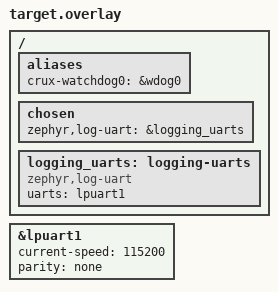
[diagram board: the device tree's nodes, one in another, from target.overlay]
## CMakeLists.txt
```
# SPDX-License-Identifier: Apache-2.0
# RT1060-EVKB bench image of the integrated management composition (HTTPS web, the command line over SSH and
# SFTP), on the Wolf profile: docs/rt1060-management-image-feasibility.md. Row C1 promoted the compile vehicle of
# stage 0 to a bench composition with a declaration (bench_declaration.json) and guards at three levels
# (bench_guard.cmake, src/bench_guard.h, Kconfig.bench). The directory keeps its name because the evidence of
# stage 0 names it. IT REFUSES TO START: CRUX_BENCH_RUN_REFUSED below is the switch, and nothing here is approved
# to run on a board. Its test certificate is not used (the certificate is generated), its SSH host key is held in
# test form (D5), and its first account comes from a password file outside the repository (D3, row C4).
# It needs the crux-secure-management west group, and a ZEPHYR_BASE with the TLS socket patch
# (scripts/prepare-wolf-tls-zephyr.sh), which the guard checks. It reuses the source lists of
# tests/native/management_composition, which refuses a board on purpose, so those lists are repeated in
# management_target.cmake and are checked there.
cmake_minimum_required(VERSION 3.20.0)
get_filename_component(CRUX_ROOT "${CMAKE_CURRENT_LIST_DIR}/../../.." ABSOLUTE)
set(composition_dir "${CRUX_ROOT}/tests/native/management_composition")
set(services_dir "${CRUX_ROOT}/tests/native/management_services")
set(EXTRA_CONF_FILE
    "${CRUX_ROOT}/tests/native/tls_offload_probe/wolf.conf"
    "${composition_dir}/profile-psa.conf"
    "${CRUX_ROOT}/components/ssh/ports/zephyr/wolf-ssh.conf"
    "${CMAKE_CURRENT_LIST_DIR}/target.conf")
set(DTC_OVERLAY_FILE
    "${CRUX_ROOT}/samples/controller/zephyr/m3-network.overlay"
    "${CMAKE_CURRENT_LIST_DIR}/target.overlay"
    "${CMAKE_CURRENT_LIST_DIR}/ram_disk.overlay")
list(APPEND ZEPHYR_EXTRA_MODULES "${CRUX_ROOT}")
find_package(Zephyr REQUIRED HINTS $ENV{ZEPHYR_BASE})
# The declaration, which no native image sets. bench_guard.cmake refuses a build without it.
set(CRUX_MANAGEMENT_BENCH_IMAGE ON)
# The refusal in main(). Removing it is a reviewed change after the approval of the board stage.
set(CRUX_BENCH_RUN_REFUSED ON)
project(crux_management_rt1060_compile LANGUAGES C)
include("${CMAKE_CURRENT_LIST_DIR}/management_target.cmake")
crux_management_target_compose()
include(${CRUX_ROOT}/cmake/CruxWebAssets.cmake)
include(${CRUX_ROOT}/cmake/CruxWebRoutes.cmake)
set(route_sources ${CRUX_WEB_SESSION_ROUTES} ${CRUX_WEB_MANAGEMENT_ROUTES}
    ${CRUX_WEB_MANAGEMENT_NETWORK_ROUTES})
target_sources(app PRIVATE src/main.c src/ssh_target.c src/bench_first_account.c ${route_sources})
# The file medium of row C3: the decision and its Zephyr glue, the only sources that mount it or format a RAM disk.
target_sources(app PRIVATE src/bench_medium.c src/bench_medium_fs.c)
if(CRUX_BENCH_RUN_REFUSED)
    target_compile_definitions(app PRIVATE CRUX_BENCH_RUN_REFUSED=1)
else()
    target_compile_definitions(app PRIVATE CRUX_BENCH_RUN_REFUSED=0)
endif()
target_include_directories(app PRIVATE src)
# Row C2: the UART report of stack watermarks, heap and the certificate fingerprint. report/ holds the parts that
# need no bench symbol (and that the host test and tests/native/bench_report build), src/bench_report.c the glue.
target_sources(app PRIVATE src/bench_report.c report/bench_report_core.c report/bench_report_format.c
    report/bench_report_policy.c)
target_include_directories(app PRIVATE report)
crux_web_assets(app FOLDER ${services_dir}/site STYLE strict)
crux_web_routes(app SOURCES ${route_sources} ZEPHYR_RESOURCES REVIEWED ${services_dir}/reviewed-routes.txt)
# Row C4 (D3): the first account's step, and its password file, which is checked here and whose bytes are embedded
# (bench_first_account.cmake). A missing, empty or short file stops the configuration.
include("${CMAKE_CURRENT_LIST_DIR}/bench_first_account.cmake")
target_sources(app PRIVATE first_account/bench_first_account_provision.c)
target_include_directories(app PRIVATE first_account)
crux_bench_first_account_prepare()
crux_bench_manifest()
# Row C9 (D11): wolfCrypt is built without RSA (CONFIG_WOLFSSL_RSA=n in target.conf, refused on at every guard level),
# and the linked image is checked for RSA code too: a module update or another definition that brings it back with the
# setting off fails the build here. It runs after the final link, and a missing image or nm is a failure, never a pass.
# zephyr_final is Zephyr's name for the final link. ZEPHYR_FINAL_EXECUTABLE is set inside Zephyr's own directory scope and
# is not visible here, so the name is written out: a rename stops the configuration at add_dependencies.
crux_bench_find_python(crux_bench_rsa_python)
add_custom_target(bench_rsa_symbols ALL
    COMMAND "${crux_bench_rsa_python}" "${CMAKE_CURRENT_LIST_DIR}/check_bench_rsa_symbols.py" --nm "${CMAKE_NM}"
            "$<TARGET_FILE:zephyr_final>"
    COMMENT "Checking the linked bench image for RSA code (D11, row C9)"
    VERBATIM)
add_dependencies(bench_rsa_symbols zephyr_final)
```

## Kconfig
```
# SPDX-License-Identifier: Apache-2.0
# The bench symbols of the RT1060-EVKB bench image. Only this application has them: any other build that
# assigns one is refused by Kconfig as an undefined symbol.
mainmenu "RT1060-EVKB bench image of the integrated management composition"

rsource "Kconfig.bench"
source "Kconfig.zephyr"
```

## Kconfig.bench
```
# SPDX-License-Identifier: Apache-2.0
# The configuration level of the bench guards (docs/rt1060-management-image-feasibility.md). A test form cannot
# take effect unless the declaration holds, and the declaration holds only on this board with the TRNG and no
# test entropy. Zephyr reports an assignment that Kconfig drops, because a dependency is not met, as a WARNING
# and goes on (the finding of docs/ssh-integrated-image.md). The CMake level turns it into a refusal: it
# requires CONFIG_CRUX_MANAGEMENT_BENCH_IMAGE and every selected form to be set.

config CRUX_MANAGEMENT_BENCH_IMAGE
	bool "Declared RT1060-EVKB rev B bench image of the integrated management composition"
	depends on BOARD_MIMXRT1060_EVK_MIMXRT1062_QSPI && BOARD_REVISION = "B"
	depends on ENTROPY_MCUX_TRNG && !TEST_RANDOM_GENERATOR && !FAKE_ENTROPY_NATIVE_SIM
	depends on !NET_DHCPV4 && !NET_IPV6
	depends on !WOLFSSL_RSA
	depends on !WOLFSSL_HAS_SETTINGS_FILE
	depends on NET_TCP_ISN_RFC6528
	help
	  The declaration that allows the test forms below, for this board and this bench only. It is the
	  Kconfig level of three: the CMake level is bench_guard.cmake and the C level is src/bench_guard.h.
	  It needs the TRNG driver and no test entropy, and no DHCP and no IPv6, because the listeners
	  answer on the one bench address (D10). It needs wolfCrypt built without RSA (D11, row C9): the declared
	  profile uses none, and a wolfSSL settings file would hide whether RSA is built. It needs the RFC 6528 initial
	  sequence number (D-c, row C11), which the build-local Zephyr copy's second patch makes fail closed: without it
	  Zephyr takes the number from sys_rand32_get() and the patch protects nothing.

if CRUX_MANAGEMENT_BENCH_IMAGE

# A test form is a way of doing something that is acceptable on a bench and is not acceptable as a
# product. Each one depends on the declaration. A symbol added here must start with CRUX_BENCH_, so that
# check_bench_guard.py finds it, and must be listed in bench_declaration.json.

config CRUX_BENCH_TEST_HOST_KEY
	bool "SSH host key in test form: a static buffer, never wiped (D5)"
	help
	  The credential store generates the key from the TRNG and the provider borrows it from a static
	  buffer for the life of the image. No product rule exists for holding and wiping a host key.

config CRUX_BENCH_NO_TIME_SOURCE
	bool "No time source: times are relative to boot (D7)"
	depends on !RTC
	help
	  Zephyr's realtime clock, which nothing sets. Certificates and events carry boot-relative times.

config CRUX_BENCH_FILE_RAM_DISK
	bool "RAM disk as the file backend (D2)"
	depends on DISK_DRIVER_RAM && !DISK_DRIVER_SDMMC
	help
	  The file service, the credential store and the events' files live on a RAM disk in SDRAM. Nothing
	  persists across a reset, and no card is touched: the SD card driver is not in the image. The
	  composition formats the RAM disk when it mounts blank, and never formats anything else
	  (src/bench_medium.c).

config CRUX_BENCH_FILE_MICROSD
	bool "microSD card as the file backend (D2). Reserved for a later run: not selected in this image"
	depends on DISK_DRIVER_SDMMC && !DISK_DRIVER_RAM
	help
	  The existing microSD provider. A later run selects it by changing the state of this form in
	  bench_declaration.json to selected, with the owner's approval of a card run and the M4 microSD
	  tools. Even then a mount that fails is reported and the card is never formatted by this image.

config CRUX_BENCH_FIRST_ACCOUNT_FILE
	bool "First account from a password in a file outside the repository (D3)"
	help
	  The password is read at configuration from the file that CRUX_BENCH_PASSWORD_FILE names, which must be private,
	  outside every git work tree and at least 16 characters, and is embedded in this image as plaintext in read-only
	  data, because Access takes a plaintext password and derives its own record. The build records the file's
	  SHA-256 in the manifest and never the password. A product creates its first account in a serial setup step.

endif # CRUX_MANAGEMENT_BENCH_IMAGE
```

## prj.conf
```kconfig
# The settings are in target.conf, which CMakeLists.txt merges last, after the Wolf profile files.
```

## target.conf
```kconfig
# RT1060-EVKB rev B bench image. Every size here is a first, unmeasured choice: the report says which.
# The bench declaration at the Kconfig level, and the test forms that it allows (Kconfig.bench). The reserved
# form CRUX_BENCH_FILE_MICROSD (a later run) stays unset until its row implements it: bench_guard.cmake refuses it
# before that.
CONFIG_CRUX_MANAGEMENT_BENCH_IMAGE=y
CONFIG_CRUX_BENCH_TEST_HOST_KEY=y
CONFIG_CRUX_BENCH_NO_TIME_SOURCE=y
# D2, row C3: the file backend is a RAM disk. See "The file backend" below.
CONFIG_CRUX_BENCH_FILE_RAM_DISK=y
# D3, row C4: the first account from a password file outside the repository (bench_first_account.cmake).
CONFIG_CRUX_BENCH_FIRST_ACCOUNT_FILE=y

# D11, row C9: wolfCrypt without RSA. The declared profile (TLS 1.3 with P-256, SSH with Ed25519 and
# ecdsa-sha2-nistp256, ECDSA and Ed25519 stored keys) uses none. The module's option defaults to y, and n defines
# NO_RSA, which drops wolfCrypt's RSA, the single-precision RSA math and wolfPSA's RSA together. Every guard level
# refuses it being on, and check_bench_rsa_symbols.py checks the linked image (docs/rt1060-bench-trim-rsa.md).
CONFIG_WOLFSSL_RSA=n

# D10: both listeners answer on the bench address only, which is the address of main.c and the declaration.
CONFIG_CRUX_WEB_BIND_ADDRESS="192.168.77.2"
CONFIG_CRUX_SSH_BIND_ADDRESS="192.168.77.2"
CONFIG_STD_C17=y
CONFIG_CRUX_PILOT_MODULE=y
CONFIG_MAIN_STACK_SIZE=16384
CONFIG_INIT_STACKS=y
CONFIG_THREAD_STACK_INFO=y
CONFIG_THREAD_NAME=y
CONFIG_THREAD_MONITOR=y
CONFIG_SHELL=n

# Crux Logging, which the security events write to: the deferred UART backend on LPUART1, as
# tests/logging_consumer configures it for this board. printk goes through it, so there is one writer.
CONFIG_PRINTK=y
CONFIG_CRUX_LOGGING=y
CONFIG_SERIAL=y
CONFIG_LOG=y
CONFIG_LOG_MODE_DEFERRED=y
CONFIG_LOG_MODE_OVERFLOW=n
CONFIG_LOG_BLOCK_IN_THREAD=n
CONFIG_LOG_PROCESS_THREAD=y
CONFIG_LOG_PROCESS_THREAD_STACK_SIZE=2048
CONFIG_LOG_PROCESS_THREAD_CUSTOM_PRIORITY=y
CONFIG_LOG_PROCESS_THREAD_PRIORITY=14
CONFIG_LOG_BUFFER_SIZE=4096
CONFIG_LOG_MAX_LEVEL=4
CONFIG_LOG_DEFAULT_LEVEL=0
CONFIG_LOG_RUNTIME_FILTERING=n
CONFIG_LOG_BACKEND_UART=y
CONFIG_LOG_BACKEND_UART_ASYNC=n
CONFIG_LOG_BACKEND_SHOW_LEVEL=y
CONFIG_UART_CONSOLE=y
CONFIG_LOG_PRINTK=y
CONFIG_STDOUT_CONSOLE=n
CONFIG_CONSOLE_HANDLER=n
CONFIG_CONSOLE_SUBSYS=n
CONFIG_EARLY_CONSOLE=n
CONFIG_BOOT_BANNER=n

# Ethernet and the TLS socket layer, as the M5 image and tests/zephyr/web_compile have them.
CONFIG_NETWORKING=y
CONFIG_NET_L2_ETHERNET=y
CONFIG_NET_IPV4=y
CONFIG_NET_IPV6=n
CONFIG_NET_TCP=y
# D-c, row C11: the TCP initial sequence number is the keyed one (RFC 6528, Zephyr's default), which the second patch
# of the build-local Zephyr copy makes fail closed. The three bench guards require it.
CONFIG_NET_TCP_ISN_RFC6528=y
CONFIG_NET_UDP=y
CONFIG_NET_SOCKETS=y
CONFIG_NET_DHCPV4=n
CONFIG_NET_CONFIG_SETTINGS=n
CONFIG_NET_BUF_POOL_USAGE=y
CONFIG_NET_MAX_CONTEXTS=32
CONFIG_NET_MAX_CONN=32
CONFIG_PHY_MONITOR_PERIOD=500
CONFIG_NET_SOCKETS_SOCKOPT_TLS=y
CONFIG_TLS_CREDENTIALS=y
CONFIG_TLS_MAX_CREDENTIALS_NUMBER=4
CONFIG_NET_SOCKETS_TLS_MAX_CONTEXTS=6
CONFIG_ZVFS_OPEN_MAX=48
CONFIG_ZVFS_POLL_MAX=24
CONFIG_ZVFS_EVENTFD=y
CONFIG_POSIX_API=y
CONFIG_POSIX_TIMERS=y
CONFIG_POSIX_THREADS=y
CONFIG_GPIO=y

# Entropy: the i.MX RT TRNG through its driver. No test generator, no fake entropy.
CONFIG_ENTROPY_GENERATOR=y
CONFIG_HWINFO=y

# The Wolf profile's arena: TLS and SSH allocate from one C library arena, in SDRAM on this board. 1 MiB since row C6:
# the paper peak of the declared sessions is 347,104 B (bench_declaration.json, heap) and stays under half of it.
CONFIG_COMMON_LIBC_MALLOC_ARENA_SIZE=1048576
CONFIG_SYS_HEAP_RUNTIME_STATS=y

# Web adapter, HTTPS only.
CONFIG_CRUX_WEB=y
# The HTTP server thread runs each TLS handshake inside accept. The static estimate of one handshake path is 4,272 B
# against the default of 4,096 B, so the owner asked for 8,192 B from the start (2026-11-08). Row C2 prints its stack
# watermark on the UART, and check_bench_uart.py fails a run that leaves under 25 percent of it (2,048 B) unused:
# the next size is 16,384 B, taken only if a board run says so. The bench declaration pins no size.
CONFIG_HTTP_SERVER_STACK_SIZE=8192

# SSH, CLI and SFTP, with the provider sizes at their defaults.
CONFIG_CRUX_SSH=y
CONFIG_CRUX_SSH_CLI=y
CONFIG_CRUX_SSH_SFTP=y
CONFIG_CRUX_SSH_PORT=22
CONFIG_CRUX_SSH_MAX_CONNECTIONS=4

# Crux capabilities the composition links.
# No CONFIG_RTC: with it the wolfSSL Zephyr port looks up a devicetree label `rtc`, which this board does not
# have (its RTC is the snvs_rtc and counter_rtc nodes, behind the `rtc` alias), and wc_port.c does not compile.
# The wall clock is then Zephyr's realtime clock, which no source sets (D7): see the report.
CONFIG_CRUX_TIME=y
CONFIG_CRUX_THREAD=y
CONFIG_CRUX_THREAD_STACK_BYTES=8192
CONFIG_CRUX_SYNC=y
CONFIG_CRUX_SYNC_MUTEX_COUNT=16
CONFIG_CRUX_NETIF=y
CONFIG_CRUX_SYSTEM=y
CONFIG_WATCHDOG=y
CONFIG_REBOOT=y

# The file backend (D2, row C3): the File service on FatFs over a RAM disk of 512 KiB in SDRAM, with no card driver in
# the image. Nothing persists across a reset: accounts, keys, the certificate and the events are lost. The disk is
# the node of ram_disk.overlay, and src/bench_medium.c formats it when it mounts blank, and never formats a card.
# CRUX_BENCH_FILE_MICROSD, the microSD provider with CRUX_FILE_FATFS_RT1060, the SD card driver and the USDHC host
# are for a later run and are refused here until the declaration says so.
CONFIG_FILE_SYSTEM=y
CONFIG_FILE_SYSTEM_MKFS=y
CONFIG_FAT_FILESYSTEM_ELM=y
CONFIG_FS_FATFS_LFN=y
CONFIG_FS_FATFS_LFN_MODE_STACK=y
CONFIG_FS_FATFS_MAX_LFN=127
CONFIG_FS_FATFS_MOUNT_MKFS=n
CONFIG_FS_FATFS_REENTRANT=y
CONFIG_FS_FATFS_NUM_FILES=6
CONFIG_DISK_DRIVERS=y
CONFIG_DISK_DRIVER_RAM=y
CONFIG_CRUX_FILE_FATFS_RT1060_RAM_DISK=y
# Zephyr turns the SD card driver and the USDHC host on by default when the board's devicetree has the card's node
# (it has), so this image turns them off. The first configure of this image showed it: the RAM disk form dropped to n
# and the CMake guard refused. With them off the image has no card driver, and no card to mount or format.
CONFIG_DISK_DRIVER_SDMMC=n
CONFIG_IMX_USDHC=n

# Row C2: what the UART report reads. TCP segments per interface tell it that a client is talking, and the SSH
# provider names its threads and keeps the figure of each worker that ended. The stack settings it also needs
# (THREAD_MONITOR, THREAD_STACK_INFO, THREAD_NAME, INIT_STACKS) and SYS_HEAP_RUNTIME_STATS are set above.
CONFIG_NET_STATISTICS=y
CONFIG_NET_STATISTICS_PER_INTERFACE=y
CONFIG_NET_STATISTICS_TCP=y
CONFIG_CRUX_SSH_STACK_REPORT=y

# Row C6: the network buffers, the TCP windows and the arena, for HTTPS, SSH and SFTP at the session sizes of D9. Every
# number is a paper rule that docs/rt1060-bench-network-buffers.md derives, and nothing is measured on a board:
# bench_guard.cmake refuses a pool under its need, a window that is not the declared one and an arena under its need
# (bench_declaration.json, network_buffers and heap), and the report's BENCH-POOL and BENCH-NET lines are what a board
# run reads to confirm or change them.
# Data buffers stay at Zephyr's 128 B. A full Ethernet frame is 12 of them, and the counts are sized in frames.
CONFIG_NET_BUF_DATA_SIZE=128
# The window is 4 segments of 1,460 B, set both ways. Left at 0, Zephyr takes a third of the pool for it, which at
# these pools is 32 KiB and 5 times the 6 frames of the driver's receive ring.
CONFIG_NET_TCP_MAX_RECV_WINDOW_SIZE=5840
CONFIG_NET_TCP_MAX_SEND_WINDOW_SIZE=5840
# 11 connections (7 slots and the web listener's backlog of 4) each holding a window of 512 B segments unread, and the
# driver's ring, with 25 percent: 915 buffers needed. Transmit: 7 queued windows and 7 senders' segments (12 buffers and
# a header buffer each): 517.
CONFIG_NET_BUF_RX_COUNT=1024
CONFIG_NET_BUF_TX_COUNT=768
CONFIG_NET_PKT_RX_COUNT=192
CONFIG_NET_PKT_TX_COUNT=32
# The driver's own default, and the session sizes (D9) and the web backlog, written down because the rule reads them.
CONFIG_ETH_NXP_ENET_RX_BUFFERS=6
CONFIG_HTTP_SERVER_MAX_CLIENTS=3
CONFIG_CRUX_WEB_BACKLOG=4
CONFIG_CRUX_SSH_WINDOW_BYTES=16384
# The pools' high-water marks, for the BENCH-POOL lines of the report. Packets are slabs, which keep no mark by default.
CONFIG_MEM_SLAB_TRACE_MAX_UTILIZATION=y
```

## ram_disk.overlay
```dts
/* SPDX-License-Identifier: Apache-2.0 */
/* The RAM disk of the RT1060-EVKB bench image (row C3, decision D2): the file backend of the first board run.
 * 524,288 B (512 KiB) in the SDRAM, which holds all RAM of this image. It is the .bss of the RAM disk driver, so it is
 * zero at every boot and nothing survives a reset. The size and its reasoning are in
 * docs/rt1060-management-image-feasibility.md; tests/native/management_rt1060_ram_disk formats exactly this node on
 * native_sim and fills it with the largest content the image's File service allows. The node is applied with
 * every build of this directory and costs nothing unless CONFIG_DISK_DRIVER_RAM is on, which the CMake guard
 * ties to the declared RAM disk form. */
/ {
    bench_ram_disk: ramdisk0 {
        compatible = "zephyr,ram-disk";
        disk-name = "RAM";
        sector-size = <512>;
        sector-count = <1024>;
    };
};
```

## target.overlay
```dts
/* SPDX-License-Identifier: Apache-2.0 */
/* The watchdog that Crux System looks up, as tests/system_consumer does for this board. */
/ { aliases { crux-watchdog0 = &wdog0; }; };

/* Crux Logging on LPUART1, the board's debug UART, as tests/logging_consumer does for this board. */
/ {
    chosen { zephyr,log-uart = &logging_uarts; };
    logging_uarts: logging-uarts {
        compatible = "zephyr,log-uart";
        uarts = <&lpuart1>;
    };
};
&lpuart1 { status = "okay"; current-speed = <115200>; parity = "none"; };
```

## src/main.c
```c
/*
 * RT1060-EVKB bench image of the integrated management composition (HTTPS web, the command line
 * over SSH and SFTP), under the bench declaration of bench_declaration.json. The test forms in it
 * (the SSH host key as a static buffer, no time source) are accepted only under that declaration.
 * The static address is the M5 image's, and the listeners answer on it only. See
 * docs/rt1060-management-image-feasibility.md.
 *
 * THIS IMAGE REFUSES TO START. Rows C2 to C9 are not done, the first account (D3) has no
 * implementation, the file backend is still the microSD provider, and the board stage has no
 * approval. Nothing here is a statement that the image may run on a board.
 */
#include "bench_first_account.h"
#include "bench_guard.h"
#include "bench_report.h"
#include "crux_native_management.h"
#include "crux_native_management_services.h"
#include "entropy_boot.h"
#include "ssh_target.h"

#include <errno.h>
#include <zephyr/kernel.h>
#include <zephyr/net/net_if.h>
#include <zephyr/sys/printk.h>

#ifndef CRUX_BENCH_RUN_REFUSED
#error "CMake sets CRUX_BENCH_RUN_REFUSED: 1 while the image refuses to start"
#endif

/* The bench address and netmask of the declaration, set before any listener starts, as
 * tests/networking_physical/main.c does for the M5 image. */
static bool static_address_up(void)
{
    struct net_if *iface = net_if_get_default();
    struct net_in_addr address, mask;

    if (iface == NULL || net_addr_pton(NET_AF_INET, CRUX_BENCH_ADDRESS, &address) != 0 ||
        net_addr_pton(NET_AF_INET, CRUX_BENCH_NETMASK, &mask) != 0 ||
        net_if_ipv4_addr_add(iface, &address, NET_ADDR_MANUAL, 0) == NULL ||
        !net_if_ipv4_set_netmask_by_addr(iface, &address, &mask)) {
        return false;
    }
    int status = net_if_up(iface);
    return status == 0 || status == -EALREADY;
}

/* D10 at run time: the interface has the bench address and no other IPv4 address, so that a
 * listener cannot answer on one that the declaration does not name. */
static bool only_bench_address(void)
{
    struct net_if *iface = net_if_get_default();
    struct net_in_addr address;
    struct net_if_ipv4 *ipv4;
    size_t used = 0;

    if (iface == NULL || net_addr_pton(NET_AF_INET, CRUX_BENCH_ADDRESS, &address) != 0 ||
        net_if_config_ipv4_get(iface, &ipv4) != 0 || ipv4 == NULL) {
        return false;
    }
    for (size_t i = 0; i < NET_IF_MAX_IPV4_ADDR; i++) {
        if (!ipv4->unicast[i].ipv4.is_used) {
            continue;
        }
        used++;
        if (!net_ipv4_addr_cmp(&ipv4->unicast[i].ipv4.address.in_addr, &address)) {
            return false;
        }
    }
    return used == 1u;
}

/* The refusal: the image is bootable, because a QSPI image needs its boot header, and it stops
 * here. The volatile read keeps all of the composition linked, so that the sizes in the report stay
 * those of the composition. The switch is CRUX_BENCH_RUN_REFUSED in ../CMakeLists.txt, and removing
 * it is a reviewed change that follows the approval of the board stage. */
static volatile const bool run_refused = CRUX_BENCH_RUN_REFUSED;

static void banner(void)
{
    printk("BENCH image=%s declaration=CRUX_MANAGEMENT_BENCH_IMAGE board=%s address=%s/%d\n",
           CRUX_BENCH_IMAGE_ID, CONFIG_BOARD_TARGET, CRUX_BENCH_ADDRESS, CRUX_BENCH_PREFIX_LENGTH);
    printk("BENCH test forms: host_key=%d no_time_source=%d ram_disk=%d first_account_file=%d\n",
           IS_ENABLED(CONFIG_CRUX_BENCH_TEST_HOST_KEY),
           IS_ENABLED(CONFIG_CRUX_BENCH_NO_TIME_SOURCE),
           IS_ENABLED(CONFIG_CRUX_BENCH_FILE_RAM_DISK),
           IS_ENABLED(CONFIG_CRUX_BENCH_FIRST_ACCOUNT_FILE));
}

static int bench_main(void)
{
    banner();
    /* The first random read, before anything makes a key and before the refusal, so that the
     * refused image prints the line too: it prints one CRUX-ENTROPY line that says which device
     * answered, and a failed read stops the image here, with no key, certificate or listener made.
     * tests/zephyr/entropy_boot, docs/rt1060-wolf-entropy.md. */
    if (!crux_entropy_boot_check()) {
        printk("BENCH refusing to start: the first random read failed, no key or listener made\n");
        return 1;
    }
    /* The refusal stops everything else: no address, store, key, certificate or listener. */
    if (run_refused) {
        printk("BENCH refusing to start: this image is not approved to run\n");
        return 1;
    }
    if (!static_address_up() || !only_bench_address()) {
        printk("BENCH address failed\n");
        return 1;
    }
    if (crux_native_management_start() != CRUX_NATIVE_MANAGEMENT_STARTED) {
        printk("BENCH composition failed\n");
        return 1;
    }
    /* The first account, only on an empty store. */
    if (crux_native_management_store_state_at_start() == CRUX_CREDENTIAL_STATE_EMPTY &&
        !crux_bench_first_account()) {
        printk("BENCH first account failed\n");
        return 1;
    }
    if (crux_native_management_services_start() != CRUX_NATIVE_MANAGEMENT_SERVICES_STARTED) {
        printk("BENCH services failed\n");
        return 1;
    }
    /* D4: the fingerprint of the certificate the listener serves, once it exists. */
    if (!crux_bench_report_certificate(crux_native_management_services_certificate_generated())) {
        printk("BENCH certificate fingerprint failed\n");
        return 1;
    }
    if (!crux_mgmt_rt1060_ssh_start()) {
        printk("BENCH ssh failed\n");
        return 1;
    }
    /* C2: the stack and heap lines at boot, after each client and at idle. */
    if (!crux_bench_report_start()) {
        printk("BENCH report failed\n");
        return 1;
    }
    printk("BENCH ready\n");
    return 0;
}

/* The main thread ends when main() returns, and the kernel's thread list then no longer shows it,
 * so its stack figure is taken here, on every way out. */
int main(void)
{
    int result = bench_main();

    crux_bench_report_main_exit();
    return result;
}
```

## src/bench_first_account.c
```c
/*
 * The first account of the RT1060-EVKB bench image (row C4, D3 of
 * docs/rt1060-management-image-feasibility.md).
 *
 * The password is in a file outside the repository. CMake checks it at configuration and embeds its
 * bytes in this image (../bench_first_account.cmake), because Access takes a plaintext password and
 * derives its own record: there is no pre-derived form to embed instead. So the plaintext IS in the
 * linked image, in read-only data in Flash, and this is a test form: it exists only here, under the
 * bench declaration, and never in a build without it. The bytes are read in place and never copied,
 * printed or logged: the lines below name the account and a result code only.
 *
 * A product does not do this. It creates its first account in a serial setup step, and gives a user
 * a public key (docs/management-in-a-product.md).
 */
#include "bench_first_account.h"

#include "bench_guard.h"

/* Before any other include, so that a build that lacks the form stops here and says why. */
#ifndef CONFIG_CRUX_BENCH_FIRST_ACCOUNT_FILE
#error                                                                                             \
    "The first account's embedded password is declared only with CONFIG_CRUX_BENCH_FIRST_ACCOUNT_FILE"
#endif
#if !defined(CRUX_BENCH_FIRST_ACCOUNT_USER) || !defined(CRUX_BENCH_FIRST_ACCOUNT_ROLE)
#error "The bench declaration did not reach the compiler: the first account's name and role"
#endif

#include "bench_first_account_provision.h"

#include <zephyr/sys/printk.h>

/* Defined by the assembler file that CMake writes beside the build, from the password file. */
extern const uint8_t crux_bench_first_account_password[];
extern const uint32_t crux_bench_first_account_password_size;

bool crux_bench_first_account(void)
{
    crux_access_result_t result = crux_bench_first_account_provision(
        CRUX_BENCH_FIRST_ACCOUNT_USER, CRUX_BENCH_FIRST_ACCOUNT_ROLE,
        crux_bench_first_account_password, crux_bench_first_account_password_size);
    if (result != CRUX_ACCESS_OK) {
        printk("BENCH first account failed: result=%d\n", (int)result);
        return false;
    }
    printk("BENCH first account created: user=%s role=%s\n", CRUX_BENCH_FIRST_ACCOUNT_USER,
           CRUX_BENCH_FIRST_ACCOUNT_ROLE);
    return true;
}
```

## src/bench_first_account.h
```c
/* The first account of the RT1060-EVKB bench image (D3), from a password in a file outside the
 * repository. Row C4 of docs/rt1060-management-image-feasibility.md implements it: see
 * bench_first_account.c and
 * ../bench_first_account.cmake. */
#ifndef CRUX_BENCH_FIRST_ACCOUNT_H
#define CRUX_BENCH_FIRST_ACCOUNT_H

#include <stdbool.h>

/* Creates the first account, which main() asks for only when the store is empty: the declared name,
 * the administrator role, and the password of the bench file, which is never printed. Returns false
 * when it did not, and then the image must not serve. */
bool crux_bench_first_account(void);

#endif
```

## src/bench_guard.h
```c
/*
 * The C level of the bench guards of the RT1060-EVKB bench image (D1 of
 * docs/rt1060-management-image-feasibility.md). Every source of this image that holds a test form
 * includes it. The CMake level is ../bench_guard.cmake and the Kconfig level is ../Kconfig.bench.
 *
 * The native guards (ssh_test_host_key_guard.h, test_tls_credentials.h, entropy_guard.h) are not
 * touched: they still refuse every board. This header accepts the test forms on one board and one
 * bench, which only ../CMakeLists.txt declares, and refuses everything else.
 * ../check_bench_guard.py compiles it with each setting broken in turn.
 */
#ifndef CRUX_BENCH_GUARD_H
#define CRUX_BENCH_GUARD_H

/* The declaration reaches C twice, from CMake and from Kconfig, and a source needs both. */
#if !defined(CRUX_MANAGEMENT_BENCH_IMAGE)
#error "A bench test form reaches a build that CMake did not declare as the RT1060-EVKB bench image"
#endif
#if !defined(CONFIG_CRUX_MANAGEMENT_BENCH_IMAGE)
#error                                                                                             \
    "A bench test form reaches a build whose Kconfig does not declare the RT1060-EVKB bench image"
#endif
#if defined(CONFIG_BOARD_NATIVE_SIM) || !defined(CONFIG_BOARD_MIMXRT1060_EVK_MIMXRT1062_QSPI) ||   \
    !defined(CONFIG_BOARD_REVISION_B)
#error "The bench image is restricted to RT1060-EVKB revision B, QSPI"
#endif
#if defined(CONFIG_TEST_RANDOM_GENERATOR) || defined(CONFIG_FAKE_ENTROPY_NATIVE_SIM) ||            \
    !defined(CONFIG_ENTROPY_MCUX_TRNG)
#error "The bench image draws its random values from the PSA provider over the TRNG driver"
#endif
/* D11, row C9: wolfCrypt is built without RSA. The declared profile uses none, one module option
 * drops it, and a settings file for wolfSSL would hide whether it is built. */
#if defined(CONFIG_WOLFSSL_RSA)
#error "The bench image has no RSA (D11): CONFIG_WOLFSSL_RSA is refused"
#endif
#if defined(CONFIG_WOLFSSL_HAS_SETTINGS_FILE)
#error "The bench image takes wolfSSL's settings from the module's Kconfig options only"
#endif
/* D-c, row C11: the TCP initial sequence number is the keyed one (RFC 6528), which the second patch
 * of the build-local Zephyr copy makes fail closed. Without the setting Zephyr takes the number
 * from sys_rand32_get(), and a test configuration skips tcp_init_isn() altogether. */
#if !defined(CONFIG_NET_TCP_ISN_RFC6528)
#error                                                                                             \
    "The bench image needs the RFC 6528 initial sequence number: CONFIG_NET_TCP_ISN_RFC6528 is required"
#endif
#if defined(CONFIG_NET_TEST) || defined(CONFIG_NET_TEST_PROTOCOL)
#error                                                                                             \
    "The bench image makes its initial sequence numbers: CONFIG_NET_TEST and CONFIG_NET_TEST_PROTOCOL are refused"
#endif
#if !defined(CRUX_BENCH_ADDRESS) || !defined(CRUX_BENCH_NETMASK) || !defined(CRUX_BENCH_IMAGE_ID)
#error "The bench declaration did not reach the compiler: address, netmask and image identity"
#endif

/* D10: both listeners are bound to the bench address and no other. The text is compared at compile
 * time, because the Zephyr server falls back to every address for a text that is not an address. */
#if !defined(CONFIG_CRUX_WEB_BIND_ADDRESS) || !defined(CONFIG_CRUX_SSH_BIND_ADDRESS)
#error "The bench image sets both listener bind addresses"
#endif
_Static_assert(__builtin_strcmp(CONFIG_CRUX_WEB_BIND_ADDRESS, CRUX_BENCH_ADDRESS) == 0,
               "The HTTPS listener must listen on the bench address only");
_Static_assert(__builtin_strcmp(CONFIG_CRUX_SSH_BIND_ADDRESS, CRUX_BENCH_ADDRESS) == 0,
               "The SSH listener must listen on the bench address only");

/* The file backend (D2, row C3): the glue and the decision of src/bench_medium*.c rely on these.
 * Each form is checked when it is set, so a source that does not use the medium compiles without
 * one. */
#if defined(CONFIG_FS_FATFS_MOUNT_MKFS)
#error "A mount never formats a card: CONFIG_FS_FATFS_MOUNT_MKFS is refused in the bench image"
#endif
#if defined(CONFIG_CRUX_BENCH_FILE_RAM_DISK) && defined(CONFIG_CRUX_BENCH_FILE_MICROSD)
#error "The bench image has exactly one file backend, and both of its forms are set"
#endif
#if defined(CONFIG_CRUX_BENCH_FILE_RAM_DISK)
#if !defined(CONFIG_CRUX_FILE_FATFS_RT1060_RAM_DISK) || !defined(CONFIG_DISK_DRIVER_RAM)
#error "The RAM disk form needs the RAM disk File provider and the RAM disk driver"
#endif
#if defined(CONFIG_CRUX_FILE_FATFS_RT1060) || defined(CONFIG_DISK_DRIVER_SDMMC) ||                 \
    defined(CONFIG_IMX_USDHC) || defined(CONFIG_DISK_DRIVER_FLASH)
#error                                                                                             \
    "The RAM disk image has no card: the microSD provider, the SD card driver, the USDHC host and the flash disk are refused"
#endif
#endif
#if defined(CONFIG_CRUX_BENCH_FILE_MICROSD)
#if !defined(CONFIG_CRUX_FILE_FATFS_RT1060) || !defined(CONFIG_DISK_DRIVER_SDMMC)
#error "The microSD form needs the microSD File provider and the SD card driver"
#endif
#if defined(CONFIG_CRUX_FILE_FATFS_RT1060_RAM_DISK) || defined(CONFIG_DISK_DRIVER_RAM)
#error "The microSD image has no RAM disk: the RAM disk provider and driver are refused"
#endif
#endif

/* A test form's own source adds its line, as ssh_target.c does:
 *   #ifndef CONFIG_CRUX_BENCH_TEST_HOST_KEY
 *   #error "..."
 *   #endif
 */

#endif
```

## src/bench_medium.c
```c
/*
 * The mount and format decision of the bench image's file medium (row C3, D2). No Zephyr header
 * here: tests/zephyr/management_rt1060_compile/host/test_bench_medium.c runs this file against fake
 * devices. See bench_medium.h for the rule.
 */
#include "bench_medium.h"
#include "bench_guard.h"

bench_medium_result_t bench_medium_prepare(bench_medium_kind_t kind, const bench_medium_ops_t *ops)
{
    if ((kind != BENCH_MEDIUM_RAM_DISK && kind != BENCH_MEDIUM_CARD) || ops == NULL ||
        ops->mount == NULL) {
        return BENCH_MEDIUM_INVALID;
    }
    if (ops->mount(ops->context) == 0) {
        return BENCH_MEDIUM_MOUNTED;
    }
    /* The one place a format is reached. A card falls through to the report below. */
    if (kind == BENCH_MEDIUM_RAM_DISK) {
        if (ops->format == NULL || ops->format(ops->context) != 0) {
            return BENCH_MEDIUM_FORMAT_FAILED;
        }
        return ops->mount(ops->context) == 0 ? BENCH_MEDIUM_FORMATTED_AND_MOUNTED
                                             : BENCH_MEDIUM_MOUNT_FAILED_AFTER_FORMAT;
    }
    return BENCH_MEDIUM_NOT_MOUNTED_NOT_FORMATTED;
}
```

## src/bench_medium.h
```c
/*
 * The file medium of the RT1060-EVKB bench image (row C3, decision D2 of
 * docs/rt1060-management-image-feasibility.md): how it is mounted, and when it may be formatted.
 *
 * The rule is one sentence: THE RAM DISK MAY BE FORMATTED AND A CARD NEVER IS. A RAM disk is memory
 * that every boot finds blank, so a failed mount is answered with a format and a second mount. A
 * card holds somebody's data, so a failed mount is the end: it is reported and nothing is written.
 *
 * bench_medium.c holds the decision, with no Zephyr in it, so that a host test can run it against
 * fake devices, including a fake card that must never be formatted. bench_medium_fs.c holds the
 * Zephyr glue, the only source of the image that names a format function.
 */
#ifndef CRUX_BENCH_MEDIUM_H
#define CRUX_BENCH_MEDIUM_H

#include <stdbool.h>
#include <stddef.h>

typedef enum {
    BENCH_MEDIUM_RAM_DISK =
        1,                /* Memory: blank at every boot, and the only kind that may be formatted */
    BENCH_MEDIUM_CARD = 2 /* A card: mounted if it mounts, and never formatted */
} bench_medium_kind_t;

typedef enum {
    BENCH_MEDIUM_MOUNTED,                   /* The medium mounted as it was */
    BENCH_MEDIUM_FORMATTED_AND_MOUNTED,     /* RAM disk only: formatted, then mounted */
    BENCH_MEDIUM_NOT_MOUNTED_NOT_FORMATTED, /* A card that did not mount: reported, nothing written
                                             */
    BENCH_MEDIUM_FORMAT_FAILED,             /* RAM disk only */
    BENCH_MEDIUM_MOUNT_FAILED_AFTER_FORMAT, /* RAM disk only: one format, one more mount, then stop
                                             */
    BENCH_MEDIUM_INVALID /* A kind that is neither, or a missing operation: no call was made */
} bench_medium_result_t;

typedef struct {
    int (*mount)(void *context);  /* 0 on success; anything else is a failure */
    int (*format)(void *context); /* Called for a RAM disk only. A card build passes NULL. */
    void *context;
} bench_medium_ops_t;

/* The whole rule. Never calls format for a kind other than BENCH_MEDIUM_RAM_DISK. */
bench_medium_result_t bench_medium_prepare(bench_medium_kind_t kind, const bench_medium_ops_t *ops);

/* The mount point of the file backend that the Kconfig form selects. bench_medium_fs.c refuses a
 * build that has neither form or both, so a source that needs the mount point has one of the two.
 */
#if defined(CONFIG_CRUX_BENCH_FILE_RAM_DISK) && !defined(CONFIG_CRUX_BENCH_FILE_MICROSD)
#define BENCH_MEDIUM_MOUNT_POINT "/RAM:"
#elif defined(CONFIG_CRUX_BENCH_FILE_MICROSD) && !defined(CONFIG_CRUX_BENCH_FILE_RAM_DISK)
#define BENCH_MEDIUM_MOUNT_POINT "/SD:"
#endif

/* Prints one BENCH line that says what was done, and returns true if the medium is mounted. */
bool bench_medium_mount(void);

#endif
```

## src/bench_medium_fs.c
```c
/*
 * The Zephyr glue of the bench image's file medium (row C3, D2): the mount, and for the RAM disk
 * the format. This is the ONLY source of the image that names a format function, and it names it
 * only in the RAM disk form, so a card build has no reference to it at all. The unit test
 * tests/build/test_management_bench_medium.py shows both, and check_mkfs_callers.py shows it on the
 * linked objects of a build. The decision is bench_medium.c.
 *
 * Which medium is chosen by the Kconfig form (Kconfig.bench, bench_declaration.json), and the CMake
 * guard refuses a build in which the provider, the disk drivers and the form disagree.
 */
#include "bench_guard.h"
#include "bench_medium.h"

#include <ff.h>
#include <stdint.h>
#include <zephyr/devicetree.h>
#include <zephyr/fs/fs.h>
#include <zephyr/sys/printk.h>

#if defined(CONFIG_CRUX_BENCH_FILE_RAM_DISK) == defined(CONFIG_CRUX_BENCH_FILE_MICROSD)
#error                                                                                             \
    "The bench image has exactly one file backend: CONFIG_CRUX_BENCH_FILE_RAM_DISK or CONFIG_CRUX_BENCH_FILE_MICROSD"
#endif

static FATFS fat;
/* FS_MOUNT_FLAG_NO_FORMAT: a failed mount is a failed mount in the file system layer too. The
 * format is ours. */
static struct fs_mount_t mount = {
    .type = FS_FATFS,
    .mnt_point = BENCH_MEDIUM_MOUNT_POINT,
    .fs_data = &fat,
    .flags = FS_MOUNT_FLAG_NO_FORMAT,
};

static int mount_medium(void *context)
{
    (void)context;
    return fs_mount(&mount);
}

#if defined(CONFIG_CRUX_BENCH_FILE_RAM_DISK)
/* The disk of the RAM disk node of ../ram_disk.overlay. A card's name is not here and cannot be
 * passed. */
#define BENCH_MEDIUM_RAM_DISK_NAME "RAM:"
#define BENCH_MEDIUM_KIND BENCH_MEDIUM_RAM_DISK
#define BENCH_RAM_DISK_BYTES                                                                       \
    ((unsigned)(DT_PROP(DT_NODELABEL(bench_ram_disk), sector_size) *                               \
                DT_PROP(DT_NODELABEL(bench_ram_disk), sector_count)))

static int format_ram_disk(void *context)
{
    (void)context;
    return fs_mkfs(FS_FATFS, (uintptr_t)BENCH_MEDIUM_RAM_DISK_NAME, NULL, 0);
}
#define BENCH_MEDIUM_FORMAT format_ram_disk
#else
#define BENCH_MEDIUM_KIND BENCH_MEDIUM_CARD
#define BENCH_MEDIUM_FORMAT NULL
#endif

bool bench_medium_mount(void)
{
    const bench_medium_ops_t ops = {
        .mount = mount_medium, .format = BENCH_MEDIUM_FORMAT, .context = NULL};
    bench_medium_result_t result = bench_medium_prepare(BENCH_MEDIUM_KIND, &ops);
    bool mounted = result == BENCH_MEDIUM_MOUNTED || result == BENCH_MEDIUM_FORMATTED_AND_MOUNTED;

#if defined(CONFIG_CRUX_BENCH_FILE_RAM_DISK)
    /* What the owner reads on the UART: where the files are, how big it is, and that it is gone at
     * a reset. */
    printk(
        "BENCH file-medium ram-disk %u B in SDRAM, %s, mounted=%d: nothing persists across a reset "
        "(accounts, keys, certificate and events are lost)\n",
        BENCH_RAM_DISK_BYTES,
        result == BENCH_MEDIUM_FORMATTED_AND_MOUNTED ? "formatted at this boot" : "found formatted",
        mounted);
#else
    printk(
        "BENCH file-medium microsd card, mounted=%d, a card is never formatted by this image%s\n",
        mounted, mounted ? "" : ": the mount failed and nothing was written");
#endif
    return mounted;
}
```

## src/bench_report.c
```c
/*
 * The bench image's report: the glue between the generic report (../report/bench_report_core.c) and
 * what only this image has. TCP segments of the one interface tell the report that a client is
 * talking (no hook in any component), the SSH provider keeps the figure of the workers that ended,
 * and the certificate module has the fingerprint. See bench_report.h.
 */
#include "bench_guard.h"

#include "bench_report.h"

#include "bench_report_core.h"
#include "bench_report_format.h"

#include "crux_ssh_wolf_provider.h"

#include <crux_tls_certificate_adapter.h>

#include <zephyr/kernel.h>
#include <zephyr/net/net_if.h>
#include <zephyr/net/net_pkt.h>
#include <zephyr/sys/printk.h>

#if !defined(CONFIG_NET_STATISTICS_PER_INTERFACE) || !defined(CONFIG_NET_STATISTICS_TCP)
#error                                                                                             \
    "The bench report counts TCP segments per interface: NET_STATISTICS_PER_INTERFACE and NET_STATISTICS_TCP"
#endif
#if !defined(CONFIG_NET_BUF_POOL_USAGE) || !defined(CONFIG_MEM_SLAB_TRACE_MAX_UTILIZATION) ||      \
    !defined(CONFIG_NET_STATISTICS_IPV4)
#error                                                                                             \
    "The bench report reads the network pools' high-water marks and the IPv4 counters (row C6): NET_BUF_POOL_USAGE, MEM_SLAB_TRACE_MAX_UTILIZATION and NET_STATISTICS_IPV4"
#endif
#if !defined(CONFIG_CRUX_SSH_STACK_REPORT)
#error "The bench report reads the SSH workers' stacks: CONFIG_CRUX_SSH_STACK_REPORT"
#endif

/* The segments received and sent on the one interface. Wraps at 2^32, which the policy allows. */
static uint32_t tcp_segments(void)
{
    struct net_if *iface = net_if_get_default();

    if (iface == NULL) {
        return 0u;
    }
    return (uint32_t)iface->stats.tcp.recv + (uint32_t)iface->stats.tcp.sent;
}

/* Row C6. The network stack's packets are memory slabs and its data buffers are net_buf pools. Both
 * keep the most that was ever in use: the pools' own high-water marks, which no component needs to
 * maintain. The size is the constant that each was built with, so that a read in the middle of an
 * allocation cannot make it wrong. */
static void slab_row(bench_report_pool_t *row, const char *name, struct k_mem_slab *slab)
{
    uint32_t used = k_mem_slab_num_used_get(slab);

    row->name = name;
    row->size = slab->info.num_blocks;
    row->used = MIN(used, row->size);
    row->peak = MIN(MAX(k_mem_slab_max_used_get(slab), row->used), row->size);
}

static void buf_row(bench_report_pool_t *row, const char *name, struct net_buf_pool *pool)
{
    uint32_t available = (uint32_t)net_buf_get_available(pool);

    row->name = name;
    row->size = pool->pool_size;
    row->used = available >= row->size ? 0u : row->size - available;
    row->peak = MIN(MAX((uint32_t)net_buf_get_max_used(pool), row->used), row->size);
}

static bool net_snapshot(bench_report_net_t *out)
{
    struct net_if *iface = net_if_get_default();
    struct k_mem_slab *rx_pkt = NULL;
    struct k_mem_slab *tx_pkt = NULL;
    struct net_buf_pool *rx_buf = NULL;
    struct net_buf_pool *tx_buf = NULL;

    if (iface == NULL) {
        return false;
    }
    net_pkt_get_info(&rx_pkt, &tx_pkt, &rx_buf, &tx_buf);
    slab_row(&out->pools[0], "rx_pkt", rx_pkt);
    slab_row(&out->pools[1], "tx_pkt", tx_pkt);
    buf_row(&out->pools[2], "rx_buf", rx_buf);
    buf_row(&out->pools[3], "tx_buf", tx_buf);
    out->pool_count = 4u;
    /* The ENET driver counts no receive drop (it has no statistics callback), so the pools' marks
     * are what shows a drop for want of a packet or a buffer. These are the counters that exist. */
    out->ip_drop = (uint32_t)iface->stats.ipv4.drop;
    out->tcp_drop = (uint32_t)iface->stats.tcp.drop;
    out->tcp_seg_drop = (uint32_t)iface->stats.tcp.seg_drop;
    out->tcp_rexmit = (uint32_t)iface->stats.tcp.rexmit;
    out->tcp_conndrop = (uint32_t)iface->stats.tcp.conndrop;
    return true;
}

/* Before each snapshot: the workers that have ended are in no thread list, so the provider's
 * figure is noted as a row of its own. The live workers are in the list under the same name. */
static void note_ended_threads(void)
{
    size_t size = 0;
    size_t unused = 0;

    if (crux_ssh_wolf_worker_stack_ended(&size, &unused)) {
        (void)bench_report_core_note_ended("ssh_worker", (uint32_t)size, (uint32_t)unused, false);
    }
}

bool crux_bench_report_start(void)
{
    static const bench_report_core_config_t config = {
        .activity = tcp_segments,
        .refresh = note_ended_threads,
        .arena_bytes = CONFIG_COMMON_LIBC_MALLOC_ARENA_SIZE,
        .net = net_snapshot,
    };
    return bench_report_core_start(&config);
}

void crux_bench_report_main_exit(void)
{
    size_t unused = 0;
    struct k_thread *self = k_current_get();

    if (k_thread_stack_space_get(self, &unused) == 0) {
        (void)bench_report_core_note_ended("main", (uint32_t)self->stack_info.size,
                                           (uint32_t)unused, true);
    }
}

bool crux_bench_report_certificate(bool generated)
{
    char fingerprint[CRUX_TLS_CERTIFICATE_FINGERPRINT_TEXT_SIZE];
    char line[BENCH_REPORT_LINE_MAX];
    crux_tls_certificate_result_t result = CRUX_TLS_CERTIFICATE_ERR_BUSY;

    /* BUSY means another operation holds the module for a moment. */
    for (int attempt = 0; attempt < 10 && result == CRUX_TLS_CERTIFICATE_ERR_BUSY; attempt++) {
        result = crux_tls_certificate_fingerprint(fingerprint);
        if (result == CRUX_TLS_CERTIFICATE_ERR_BUSY) {
            k_msleep(20);
        }
    }
    if (result != CRUX_TLS_CERTIFICATE_OK ||
        bench_report_format_cert(line, sizeof(line), fingerprint, generated) == 0u) {
        printk("BENCH-CERT unavailable\n");
        return false;
    }
    printk("%s\n", line);
    return true;
}
```

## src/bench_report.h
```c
/*
 * What the bench image reports on the UART so that a board run can read its stack and heap limits
 * and check its listener certificate (row C2 of docs/rt1060-management-image-feasibility.md). The
 * lines and their grammar are in ../report/bench_report_format.h, and check_bench_uart.py judges
 * them.
 */
#ifndef CRUX_MGMT_RT1060_BENCH_REPORT_H
#define CRUX_MGMT_RT1060_BENCH_REPORT_H

#include <stdbool.h>

/**
 * D4: prints once the SHA-256 fingerprint of the certificate that the certificate module made
 * active and that the services handed to the TLS credentials, as
 * `BENCH-CERT v=1 sha256=AA:BB:..:FF source=generated`. Call it after the services have started.
 * Returns false, with `BENCH-CERT unavailable` printed, when the module has no fingerprint or the
 * text is not 32 uppercase pairs: the image must not look ready then.
 */
bool crux_bench_report_certificate(bool generated);

/** Starts the thread that prints the stack, heap, network pool and counter lines at boot, after
 * each client and at idle. */
bool crux_bench_report_start(void);

/**
 * Records the calling thread's stack as the main thread's final figure. Call it as the last thing
 * main() does, because the main thread ends when main() returns and the kernel's list no longer
 * shows it. Safe before the report has started.
 */
void crux_bench_report_main_exit(void);

#endif
```

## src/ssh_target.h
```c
/* SSH start for the RT1060-EVKB bench image: see ../CMakeLists.txt. */
#ifndef CRUX_MGMT_RT1060_SSH_TARGET_H
#define CRUX_MGMT_RT1060_SSH_TARGET_H

#include <stdbool.h>

/* The host key from the credential store into a static buffer that is never wiped: TEST FORM (D5),
 * allowed only under the bench declaration. Returns false when the host key, the CLI provider or
 * the listener did not start. */
bool crux_mgmt_rt1060_ssh_start(void);

#endif
```
